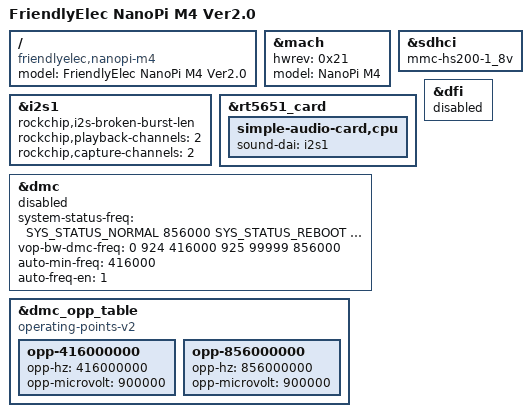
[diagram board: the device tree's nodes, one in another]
/*
 * Copyright (c) 2018 FriendlyElec Computer Tech. Co., Ltd.
 * (http://www.friendlyarm.com)
 *
 * This program is free software; you can redistribute it and/or
 * modify it under the terms of the GNU General Public License
 * as published by the Free Software Foundation; either version 2
 * of the License, or (at your option) any later version.
 *
 * This program is distributed in the hope that it will be useful,
 * but WITHOUT ANY WARRANTY; without even the implied warranty of
 * MERCHANTABILITY or FITNESS FOR A PARTICULAR PURPOSE.  See the
 * GNU General Public License for more details.
 *
 * You should have received a copy of the GNU General Public License
 * along with this program.  If not, see <http://www.gnu.org/licenses/>.
 */

/dts-v1/;
#include "rk3399-nanopi4-common.dtsi"

/ {
	model = "FriendlyElec NanoPi M4 Ver2.0";
	compatible = "friendlyelec,nanopi-m4", "rockchip,rk3399";
};

&mach {
	hwrev = <0x21>;
	model = "NanoPi M4";
};

&sdhci {
	mmc-hs200-1_8v;
	/delete-property/ mmc-hs400-1_8v;
	/delete-property/ mmc-hs400-enhanced-strobe;
};

&i2s1 {
	status = "okay";
	rockchip,i2s-broken-burst-len;
	rockchip,playback-channels = <2>;
	rockchip,capture-channels = <2>;
	#sound-dai-cells = <0>;
};

&rt5651_card {
	/delete-property/ pinctrl-0;
	/delete-property/ simple-audio-card,hp-det-gpio;

	simple-audio-card,cpu {
		sound-dai = <&i2s1>;
	};
};

&dfi {
	status = "disabled";
};

&dmc {
	status = "disabled";
	system-status-freq = <
		/*system status         freq(KHz)*/
		SYS_STATUS_NORMAL       856000
		SYS_STATUS_REBOOT       416000
		SYS_STATUS_SUSPEND      416000
		SYS_STATUS_VIDEO_1080P  856000
		SYS_STATUS_VIDEO_4K     856000
		SYS_STATUS_VIDEO_4K_10B 856000
		SYS_STATUS_PERFORMANCE  856000
		SYS_STATUS_BOOST        856000
		SYS_STATUS_DUALVIEW     856000
		SYS_STATUS_ISP          856000
	>;
	vop-bw-dmc-freq = <
	/* min_bw(MB/s) max_bw(MB/s) freq(KHz) */
		0       924      416000
		925     99999    856000
	>;
	auto-min-freq = <416000>;
	auto-freq-en = <1>;
};

&dmc_opp_table {
	compatible = "operating-points-v2";

	/delete-node/ opp-200000000;
	/delete-node/ opp-300000000;
	/delete-node/ opp-400000000;
	/delete-node/ opp-528000000;
	/delete-node/ opp-600000000;
	/delete-node/ opp-800000000;

	opp-416000000 {
		opp-hz = /bits/ 64 <416000000>;
		opp-microvolt = <900000>;
	};
	opp-856000000 {
		opp-hz = /bits/ 64 <856000000>;
		opp-microvolt = <900000>;
	};
};
